# cyt4dn register map
Vendor: Cypress Semiconductor; Series: cyt4dn; File version: 1.0
CPU: CM7 r0p1, little endian, MPU, FPU, VTOR, 3 interrupt priority bits
Registers are 32-bit, read-write, reset 0x0 unless marked. A register's access mark holds for its fields unless they carry their own. Offsets are from the block's base; [hi:lo] are bit positions; lines under a group give offsets from that group; {n}, {i} and the like mark numbered series; 'fields as' and 'values as' point back to an identical list.

## VIDEOSS0 (part 7 of 18) — Video and Graphics Subsystem IP
Base 0x40A00000
0x80000 VIDEOIO group — Video I/O Core
  0x00 SUBIO group — Sub Interface
    0x10000 COMPENG group — Composition Engine
      0x4800 FETCHLAYER0 group — FetchLayer #0 (Display)
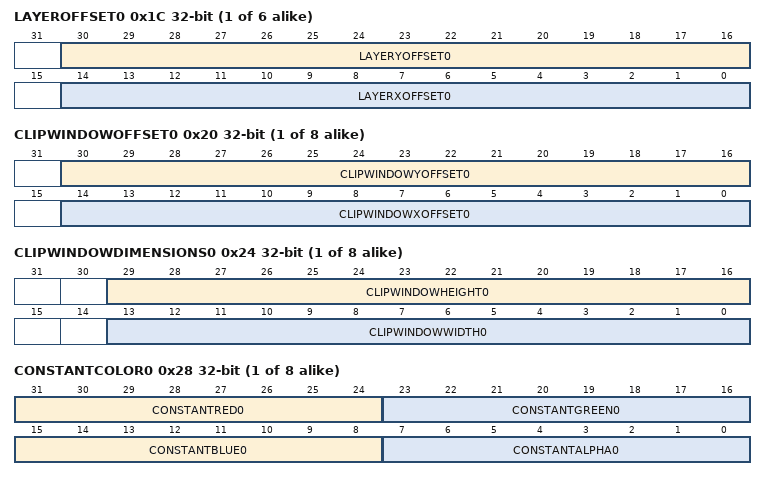
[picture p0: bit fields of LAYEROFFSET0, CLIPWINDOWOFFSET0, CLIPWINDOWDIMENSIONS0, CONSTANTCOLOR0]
        {0x1C+0x28*m} LAYEROFFSET{m} (m=0..5) — Position of layer {m} within the destination frame.
          [30:16] LAYERYOFFSET{m} — Vertical offset (Y). (format is signed integer)
          [14:0] LAYERXOFFSET{m} — Horizontal offset (X). (format is signed integer)
        {0x20+0x28*m} CLIPWINDOWOFFSET{m} (m=0..7) — Clip window position for layer {m}.
          [30:16] CLIPWINDOWYOFFSET{m} — Vertical position (Y). (format is signed integer)
          [14:0] CLIPWINDOWXOFFSET{m} — Horizontal position (X). (format is signed integer)
        {0x24+0x28*m} CLIPWINDOWDIMENSIONS{m} (m=0..7) — Clip window size for layer {m}.
          [29:16] CLIPWINDOWHEIGHT{m} — Height.
          [13:0] CLIPWINDOWWIDTH{m} — Width.
        {0x28+0x28*m} CONSTANTCOLOR{m} (m=0..7) — Constant color for layer {m}.
          [31:24] CONSTANTRED{m} — Red and Y (luma).
          [23:16] CONSTANTGREEN{m} — Green and U (chroma).
          [15:8] CONSTANTBLUE{m} — Blue and V (chroma).
          [7:0] CONSTANTALPHA{m} — Alpha.
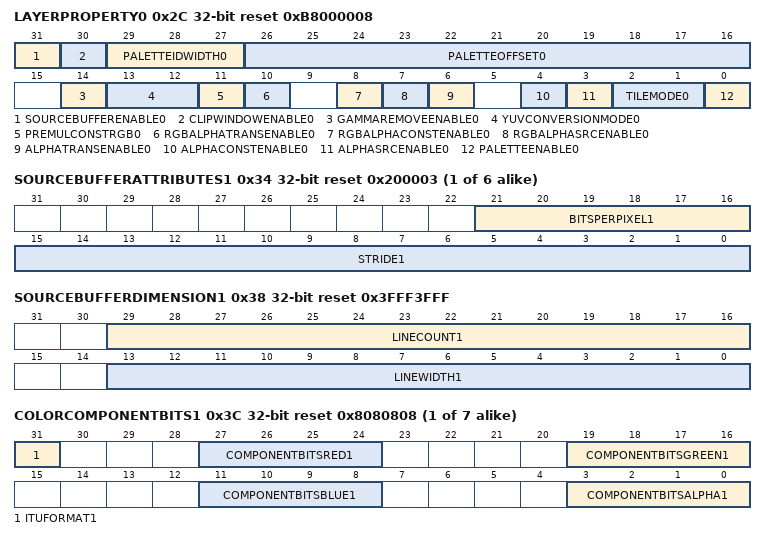
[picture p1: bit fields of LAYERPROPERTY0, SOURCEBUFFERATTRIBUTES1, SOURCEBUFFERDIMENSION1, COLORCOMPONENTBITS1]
        0x2C LAYERPROPERTY0 reset 0xB8000008 — Common properties of layer 0.
          [31] SOURCEBUFFERENABLE0 — Value 1 enables the source buffer for this layer. When disabled the tiling color is used only (TileMode TILE_PAD not allowed).
          [30] CLIPWINDOWENABLE0 — Value 1 enables the clip window for this layer. Pixels outside the clip window get the clip color, pixels inside the source or tiling color.
          [29:27] PALETTEIDWIDTH0 — Number minus one of least significant bits of pixel data read from the source buffer that are used as index value for color palette look-up.
          [26:16] PALETTEOFFSET0 — Palette may contain multiple areas. This offset shows to the starting position of the currently used area.
          [14] GAMMAREMOVEENABLE0 — Value 1 enables the stage to remove a gamma from RGB components.
          [13:12] YUVCONVERSIONMODE0 — Enables different kind of YUV to RGB conversions.
            0=OFF (No conversion.); 1=ITU601 (Conversion from YCbCr (YUV) to RGB according to ITU recommendation BT.601-6 (standard definition TV). Input range is 16..235 for Y and 16..240 for U/V.); 2=ITU601_FR (Conversion from YCbCr (YUV) to RGB according to ITU recommendation BT.601-6, but assuming full range YUV inputs (0..255). Most typically used for computer graphics (e.g. for JPEG encoding).); 3=ITU709 (Conversion from YCbCr (YUV) to RGB according to ITU recommendation BT.709-5 part 2 (high definition TV). Input range is 16..235 for Y and 16..240 for U/V.)
          [11] PREMULCONSTRGB0 — When enabled (value 1) the values given by ConstantRed/Green/Blue are used instead of alpha for source RGB pre-multiply. Settings RGBAlphaSrc/Const/Mask/TransEnable have no effect then.
          [10] RGBALPHATRANSENABLE0 — Value 1 enables transparent alpha (0 or 1 depending on RGB matching ConstantColor setting) for RGB pre-multiply. When disabled transparent alpha is set to 1.
          [8] RGBALPHACONSTENABLE0 — Value 1 enables constant alpha (ConstAlpha fields) for RGB pre-multiply. When disabled constant alpha is set to 1.
          [7] RGBALPHASRCENABLE0 — Value 1 enables source alpha (stored together with color component in the source buffer) for RGB pre-multiply. When disabled source alpha is set to 1.
          [6] ALPHATRANSENABLE0 — Value 1 enables transparent alpha for computing the output alpha. When disabled transparent alpha is set to 1.
          [4] ALPHACONSTENABLE0 — Value 1 enables constant alpha for computing the output alpha. When disabled constant alpha is set to 1.
          [3] ALPHASRCENABLE0 — Value 1 enables source alpha for computing the output alpha. When disabled source alpha is set to 1.
          [2:1] TILEMODE0 — Select the tile mode for pixels outside the source buffer. Clip color (0,0,0,0) takes precedence if a pixel becomes subject to both tiling and clipping.
            0=TILE_FILL_ZERO (Use zero value); 1=TILE_FILL_CONSTANT (Use constant color register value); 2=TILE_PAD (Use closest pixel from source buffer. Must not be used for DECODE or YUV422 operations or when SourceBufferEnable is 0.); 3=TILE_PAD_ZERO (Use closest pixel from source buffer but zero for alpha component. Must not be used for DECODE or YUV422 operations or when SourceBufferEnable is 0.)
          [0] PALETTEENABLE0 — Enables (value = 1) a color palette with 8 bits input and 24 bits output. Lower bits of the lookup index are read from memory (PaletteIdWidth0), upper bits are set to index of this layer. Palette output is extended by upper bits of index word read from memory (e.g. to store alpha together with index). Result is mapped to color channels according to ColorComponentBits/Shift settings.
        {0x8+0x28*m} BASEADDRESS{m} (m=1..7) — Source buffer base address of layer {m}.
          [31:0] BASEADDRESS{m} — See BaseAddress0.
        {0xC+0x28*m} SOURCEBUFFERATTRIBUTES{m} reset 0x200003 (m=1..6) — Source buffer attributes for layer {m}.
          [21:16] BITSPERPIXEL{m} — See BitsPerPixel0.
          [15:0] STRIDE{m} — See Stride0.
        0x38 SOURCEBUFFERDIMENSION1 reset 0x3FFF3FFF — Source buffer dimensions of layer 1,
          [29:16] LINECOUNT1 — See LineCount0.
          [13:0] LINEWIDTH1 — See LineWidth0.
        {0x14+0x28*m} COLORCOMPONENTBITS{m} reset 0x8080808 (m=1..7) — Size of color components for RGB, YUV and index formats (layer {m}).
          [31] ITUFORMAT{m} — See ITUFormat0.
          [27:24] COMPONENTBITSRED{m} — Red, Y (luma) and palette index.
          [19:16] COMPONENTBITSGREEN{m} — Green and U (chroma).
          [11:8] COMPONENTBITSBLUE{m} — Blue and V (chroma).
          [3:0] COMPONENTBITSALPHA{m} — Alpha.
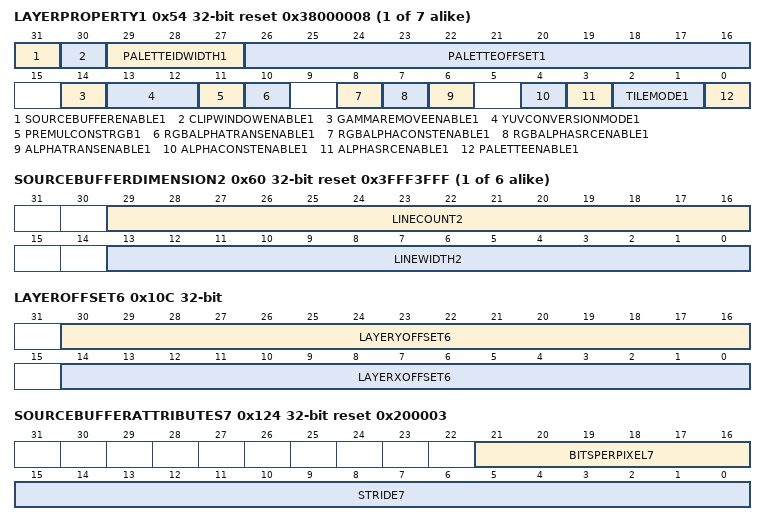
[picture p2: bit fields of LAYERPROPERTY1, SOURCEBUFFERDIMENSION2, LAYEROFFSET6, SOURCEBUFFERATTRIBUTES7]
        {0x2C+0x28*m} LAYERPROPERTY{m} reset 0x38000008 (m=1..7) — Common properties of layer {m}.
          [31] SOURCEBUFFERENABLE{m} — See SourceBufferEnable0.
          [30] CLIPWINDOWENABLE{m} — See ClipWindowEnable0.
          [29:27] PALETTEIDWIDTH{m} — see PaletteIdWidth0.
          [26:16] PALETTEOFFSET{m} — see PaletteOffset0.
          [14] GAMMAREMOVEENABLE{m} — See GammaRemoveEnable0.
          [13:12] YUVCONVERSIONMODE{m} — See YUVConversionMode0.
            values as VIDEOIO.SUBIO.COMPENG.FETCHLAYER0.LAYERPROPERTY0.YUVCONVERSIONMODE0
          [11] PREMULCONSTRGB{m} — See PremulConstRGB0.
          [10] RGBALPHATRANSENABLE{m} — See RGBAlphaTransSelect0.
          [8] RGBALPHACONSTENABLE{m} — See RGBAlphaConstSelect0.
          [7] RGBALPHASRCENABLE{m} — See RGBAlphaSrcSelect0.
          [6] ALPHATRANSENABLE{m} — See AlphaTransSelect0.
          [4] ALPHACONSTENABLE{m} — See AlphaConstSelect0.
          [3] ALPHASRCENABLE{m} — See AlphaSrcSelect0.
          [2:1] TILEMODE{m} — See TileMode0.
            values as VIDEOIO.SUBIO.COMPENG.FETCHLAYER0.LAYERPROPERTY0.TILEMODE0
          [0] PALETTEENABLE{m} — See PaletteEnable0.
        {0x10+0x28*m} SOURCEBUFFERDIMENSION{m} reset 0x3FFF3FFF (m=2..7) — Source buffer dimension of layer {m}.
          [29:16] LINECOUNT{m} — See LineCount0.
          [13:0] LINEWIDTH{m} — See LineWidth0.
        0x10C LAYEROFFSET6 — Position of layer 1 within the destination frame.
          [30:16] LAYERYOFFSET6 — Vertical offset (Y). (format is signed integer)
          [14:0] LAYERXOFFSET6 — Horizontal offset (X). (format is signed integer)
        0x124 SOURCEBUFFERATTRIBUTES7 reset 0x200003 — Source buffer stride for layer 7.
          [21:16] BITSPERPIXEL7 — See BitsPerPixel0.
          [15:0] STRIDE7 — See Stride0.
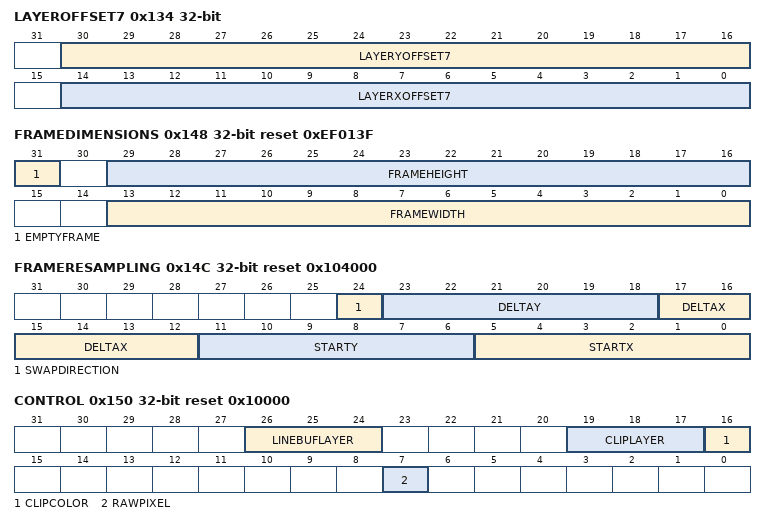
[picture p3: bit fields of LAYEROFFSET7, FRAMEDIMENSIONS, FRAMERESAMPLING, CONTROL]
        0x134 LAYEROFFSET7 — Position of layer 7 within the destination frame.
          [30:16] LAYERYOFFSET7 — Vertical offset (Y). (format is signed integer)
          [14:0] LAYERXOFFSET7 — Horizontal offset (X). (format is signed integer)
        0x148 FRAMEDIMENSIONS reset 0xEF013F — Output frame dimension.
          [31] EMPTYFRAME — When enabled output frame is empty. FrameWidth/Height settings have no effect then. Can be used to load shadows or to generate synchronization signals only (frame/sequence complete). If enabled, InputSelect must be set to INACTIVE.
          [29:16] FRAMEHEIGHT — Frame height minus one.
          [13:0] FRAMEWIDTH — Frame width minus one.
        0x14C FRAMERESAMPLING reset 0x104000 — Resampling options for output frame.
          [24] SWAPDIRECTION — Swaps X and Y directions for re-sampling. When enabled (= 1) DeltaY is applied for horizontal and DeltaX for vertical step on destination frame.
          [23:18] DELTAY — Increment of Y coordinate for vertical step in destination frame. (format is signed fix-point 4.2)
          [17:12] DELTAX — Increment of X coordinate for horizontal step in destination frame. (format is signed fix-point 4.2)
          [11:6] STARTY — Y coordinate of first sample point relative to origin. (format is signed fix-point 4.2)
          [5:0] STARTX — X coordinate of first sample point relative to origin. (format is signed fix-point 4.2)
        0x150 CONTROL reset 0x10000 — Shared common control settings for all layers.
          [26:24] LINEBUFLAYER — Index of the layer which used as a memory based linebuffer. Only has an effect if this fetch unit is connected to a store unit for linebuffer handshake and linebuffer handshake is enabled.
          [19:17] CLIPLAYER — Index of the layer which is used to fill the clipping area of the frame layout when ClipColor is set to LAYER. The selected layer must be enabled (LayerEnable).
          [16] CLIPCOLOR — Selects which color to take for pixels that do not lie inside the clip window of any layer.
            0=NULL (Null color.); 1=LAYER (Color of layer number given by ClipLayer (or layer 0 when Fetch unit has one layer only). The color is then the layer's source or tiling color.)
          [7] RAWPIXEL — Raw pixel mode. If enabled (value = 1), the ComponentBits/Shift settings are replaced for all layers by fixed values that allow passing the pixel data read from memory unchanged to subsequent units (e.g. for reading coordinate layers). Multiply stages and transparent color are deactivated. Skip and Tile pixels are not affected by this setting.
        0x154 TRIGGERENABLE — Shadow load enable flags for all layers.
          [7:0] SHDLDREQ — Shadow load request flags for each layer (one time load).
        0x158 CONTROLTRIGGER wo reset not defined — Shadow load trigger.
          [0] SHDTOKGEN — Writing a 1 to this will load shadow registers into the active configuration with the next start of frame and send a shadow load token to subsequent units.
        0x15C START wo reset not defined — Frame start trigger.
          [0] START — Writing a 1 to this field will start generating one frame (for debugging purposes only).
        0x160 FETCHTYPE ro reset not defined — Fetch unit type.
          [3:0] FETCHTYPE — This field can be used to determine what kind of fetch unit this is.
            0=DECODE (Fetch unit with RL and RLAD decoder.); 1=LAYER (Fetch unit with fractional plane (8 layers).); 2=WARP (Fetch unit with arbitrary warping and fractional plane (8 layers).); 3=ECO (Fetch unit with minimum feature set for alpha, chroma and coordinate planes.); 4=PERSP (Fetch unit with affine, perspective and arbitrary warping.); 5=ROT (Fetch unit with affine and arbitrary warping.); 6=DECODEL (Fetch unit with RL and RLAD decoder, reduced feature set.); 7=LAYERL (Fetch unit with fractional plane (8 layers), reduced feature set.); 8=ROTL (Fetch unit with affine and arbitrary warping, reduced feature set.); 9=ECOL (Fetch unit with reduced minimum feature set for alpha, chroma and coordinate planes.); 10=BLIT (Fetch unit with DECODE and PERSP capabilities.)
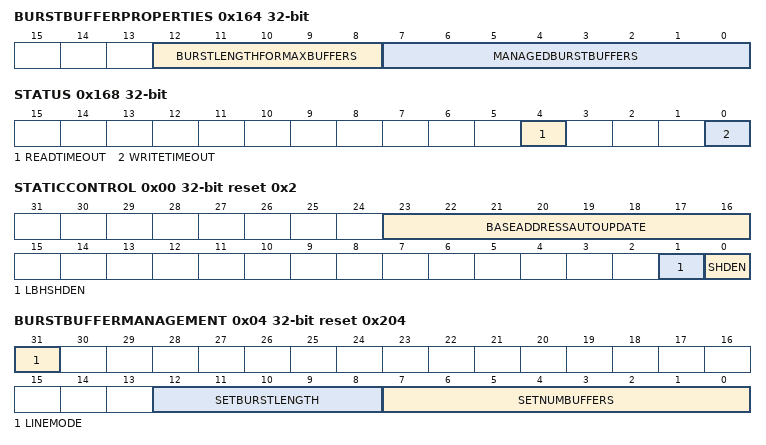
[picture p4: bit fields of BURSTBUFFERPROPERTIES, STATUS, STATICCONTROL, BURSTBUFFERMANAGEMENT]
        0x164 BURSTBUFFERPROPERTIES ro reset not defined
          [12:8] BURSTLENGTHFORMAXBUFFERS — Maximum Burst Length that can be used when ManagedBurstBuffers burst buffers are used.
          [7:0] MANAGEDBURSTBUFFERS — Maximum number of burst buffers that can be administrated in the AXI interface.
        0x168 STATUS — Status information.
          [4] READTIMEOUT — Timeout detected when reading from the palette entries or shadow token trigger enables in FetchLayer derivate. Write 1 to clear.
          [0] WRITETIMEOUT — Timeout detected when writing to the palette entries or shadow token trigger enables in FetchLayer derivate. Write 1 to clear.
      0x4C00 FETCHDECODE4 group — FetchDecode #4 (Capture)
        0x00 STATICCONTROL reset 0x2 — Common static control options.
          [23:16] BASEADDRESSAUTOUPDATE — Enable flag for continuous shadow load of BaseAddress field for each layer (layer index = bit index). When set to 1 the active BaseAddress configuration is loaded from shadow at start of each frame. This update is then executed independently from other RWS type fields. ShdEn must be enabled for this mode. When the flag is enabled for layer 0, also the FieldId0 shadow is automatically loaded.
          [1] LBHSHDEN — Enables shadowing of LBH configuration signals.
          [0] SHDEN — Enables shadowing of all RWS type registers (0=write_through, 1=shadowed).
        0x04 BURSTBUFFERMANAGEMENT reset 0x204 — AXI interface buffer management register
          [31] LINEMODE — Fetch buffer cache control.
            0=DISPLAY (Mandatory setting for operation in the Display Controller. Works also for Blit Engine with marginal performance impact.); 1=BLIT (Recommended setting for operation in the Blit Engine.)
          [12:8] SETBURSTLENGTH — Set this to the burst length that should be used on the AXI interface. SetNumBuffers * SetBurstLength has to be smaller or equal to ManagedBurstBuffers * BurstLengthForMaxBuffers and that bursts larger than 16 are not possible on the axi interface. Only a power of two may be specified as burst length.
          [7:0] SETNUMBUFFERS — Set this to the number of bursts that should be buffered. SetNumBuffers has to be smaller or equal to ManagedBurstBuffers and SetNumBuffers * SetBurstLength has to be smaller or equal to ManagedBurstBuffers * BurstLengthForMaxBuffers. Must be a power of 2. The minimum allowed settings is 4 except for the FetchEco derivate which has a minimum allowed setting of 2.
        0x08 RINGBUFSTARTADDR0 — Ring buffer setup for layer 0.
          [31:0] RINGBUFSTARTADDR0 — Start address of the ring buffer. Must be aligned to SetBurstLength x 8 bytes.
        0x0C RINGBUFWRAPADDR0 — Ring buffer setup for layer 0.
          [31:0] RINGBUFWRAPADDR0 — End address of the ring buffer (last byte of the buffer plus one).
        0x10 FRAMEPROPERTIES0 — Frame property setup for layer 0.
          [0] FIELDID0 — Field identifier that is generated for subsequent units (0 = progressive frame or interlaced field with even line indices, 1 = odd field).
        0x14 BASEADDRESS0 — Source buffer base address of layer 0.
          [31:0] BASEADDRESS0 — Byte aligned start address of the layer source buffer. For a pixel width of 32 bits or DECODE operations BaseAddress bits 1 downto 0 have to be 0 and for a pixel width of 16 bit BaseAddress[0] has to be 0.
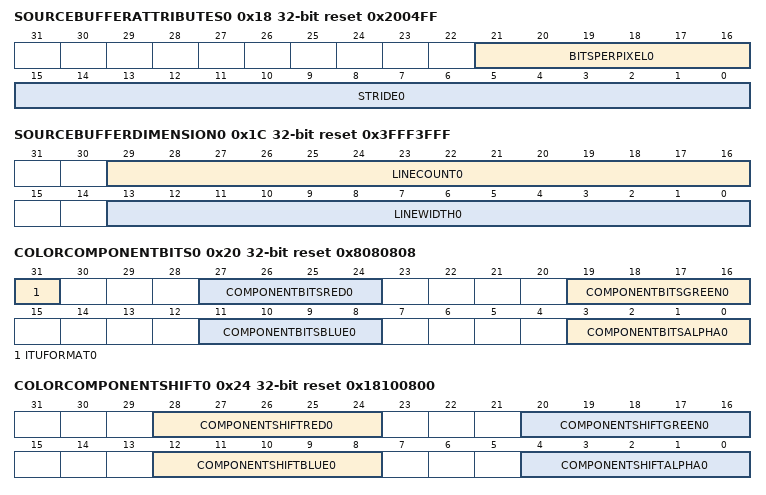
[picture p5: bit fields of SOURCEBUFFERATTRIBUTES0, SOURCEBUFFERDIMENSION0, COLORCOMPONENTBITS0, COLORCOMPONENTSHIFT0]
        0x18 SOURCEBUFFERATTRIBUTES0 reset 0x2004FF — Source buffer attributes for layer 0.
          [21:16] BITSPERPIXEL0 — Number of bits per pixel in the source buffer. Must be 1, 2, 4, 8, 16, 18, 24 or 32. [Exception] FetchEco does not support 18 and 24.
          [15:0] STRIDE0 — Source buffer stride of the layer in bytes minus one, used for address generation. For a pixel width of 32 bits Stride has to be dividable by 4 and given minus one and for a pixel width of 16 bit Stride has to be dividable by two and given minus one.
        0x1C SOURCEBUFFERDIMENSION0 reset 0x3FFF3FFF — Source buffer dimension of layer 0.
          [29:16] LINECOUNT0 — Number of lines of the source buffer of the layer minus one.
          [13:0] LINEWIDTH0 — Width of the source buffer of the layer in pixels minus one.
        0x20 COLORCOMPONENTBITS0 reset 0x8080808 — Size of color components for RGB, YUV and index formats (layer 0).
          [31] ITUFORMAT0 — When ComponentBitsRed/Green/Blue is set to 10 and this mode enabled (value 1), then input format is considered 8.2 instead of 10.0 bits (max color is 1020 instead of 1023). This is compliant to ITU 656 standard.
          [27:24] COMPONENTBITSRED0 — Red, Y (luma) and palette index.
          [19:16] COMPONENTBITSGREEN0 — Green and U (chroma).
          [11:8] COMPONENTBITSBLUE0 — Blue and V (chroma).
          [3:0] COMPONENTBITSALPHA0 — Alpha.
        0x24 COLORCOMPONENTSHIFT0 reset 0x18100800 — Bit position of color components for RGB, YUV and index formats (layer 0).
          [28:24] COMPONENTSHIFTRED0 — Red, Y (luma) and palette index.
          [20:16] COMPONENTSHIFTGREEN0 — Green and U (chroma).
          [12:8] COMPONENTSHIFTBLUE0 — Blue and V (chroma).
          [4:0] COMPONENTSHIFTALPHA0 — Alpha.
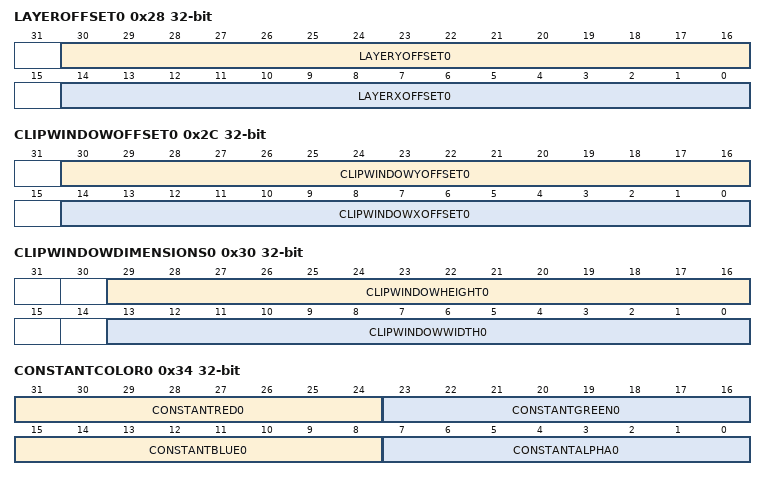
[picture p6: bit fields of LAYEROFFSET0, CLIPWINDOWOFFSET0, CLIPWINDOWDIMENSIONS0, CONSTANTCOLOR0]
        0x28 LAYEROFFSET0 — Position of layer 0 within the destination frame.
          [30:16] LAYERYOFFSET0 — Vertical offset (Y). (format is signed integer)
          [14:0] LAYERXOFFSET0 — Horizontal offset (X). (format is signed integer)
        0x2C CLIPWINDOWOFFSET0 — Clip window position for layer 0.
          [30:16] CLIPWINDOWYOFFSET0 — Vertical position (Y). (format is signed integer)
          [14:0] CLIPWINDOWXOFFSET0 — Horizontal position (X). (format is signed integer)
        0x30 CLIPWINDOWDIMENSIONS0 — Clip window size for layer 0.
          [29:16] CLIPWINDOWHEIGHT0 — Height.
          [13:0] CLIPWINDOWWIDTH0 — Width.
        0x34 CONSTANTCOLOR0 — Constant color for layer 0.
          [31:24] CONSTANTRED0 — Red and Y (luma).
          [23:16] CONSTANTGREEN0 — Green and U (chroma).
          [15:8] CONSTANTBLUE0 — Blue and V (chroma).
          [7:0] CONSTANTALPHA0 — Alpha.
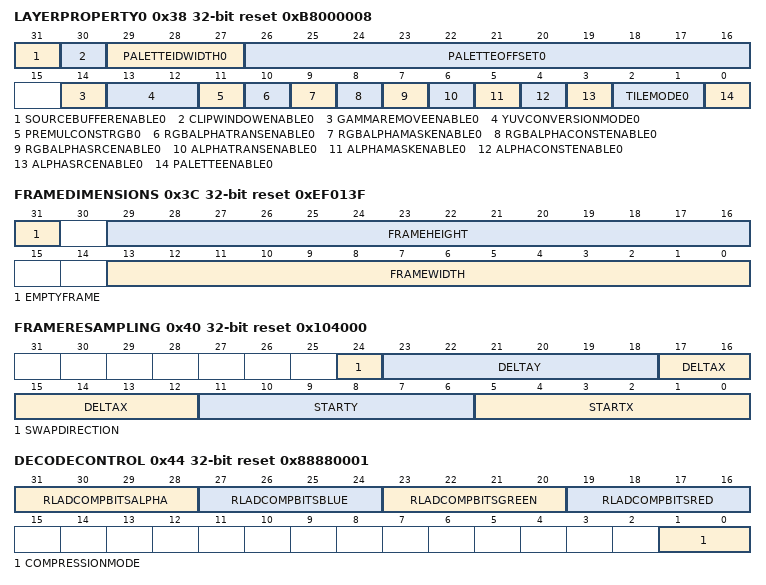
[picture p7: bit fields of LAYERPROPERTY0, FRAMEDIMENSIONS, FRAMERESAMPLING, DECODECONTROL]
        0x38 LAYERPROPERTY0 reset 0xB8000008 — Common properties of layer 0.
          [31] SOURCEBUFFERENABLE0 — Value 1 enables the source buffer for this layer. When disabled the tiling color is used only (TileMode TILE_PAD not allowed).
          [30] CLIPWINDOWENABLE0 — Value 1 enables the clip window for this layer. Pixels outside the clip window get the clip color, pixels inside the source or tiling color.
          [29:27] PALETTEIDWIDTH0 — Number minus one of least significant bits of pixel data read from the source buffer that are used as index value for color palette look-up.
          [26:16] PALETTEOFFSET0 — Palette may contain multiple areas. This offset shows to the starting position of the currently used area.
          [14] GAMMAREMOVEENABLE0 — Value 1 enables the stage to remove a gamma from RGB components.
          [13:12] YUVCONVERSIONMODE0 — Enables different kind of YUV to RGB conversions.
            values as VIDEOIO.SUBIO.COMPENG.FETCHLAYER0.LAYERPROPERTY0.YUVCONVERSIONMODE0
          [11] PREMULCONSTRGB0 — When enabled (value 1) the values given by ConstantRed/Green/Blue are used instead of alpha for source RGB pre-multiply. Settings RGBAlphaSrc/Const/Mask/TransEnable have no effect then.
          [10] RGBALPHATRANSENABLE0 — Value 1 enables transparent alpha (0 or 1 depending on RGB matching ConstantColor setting) for RGB pre-multiply. When disabled transparent alpha is set to 1.
          [9] RGBALPHAMASKENABLE0 — Value 1 enables mask alpha (read by another Fetch unit from a separate alpha layer) for RGB pre-multiply. When disabled mask alpha is set to 1. Alpha mask input must be enabled for this field to have effect.
          [8] RGBALPHACONSTENABLE0 — Value 1 enables constant alpha (ConstAlpha fields) for RGB pre-multiply. When disabled constant alpha is set to 1.
          [7] RGBALPHASRCENABLE0 — Value 1 enables source alpha (stored together with color component in the source buffer) for RGB pre-multiply. When disabled source alpha is set to 1.
          [6] ALPHATRANSENABLE0 — Value 1 enables transparent alpha for computing the output alpha. When disabled transparent alpha is set to 1.
          [5] ALPHAMASKENABLE0 — Value 1 enables mask alpha for computing the output alpha. When disabled mask alpha is set to 1.
          [4] ALPHACONSTENABLE0 — Value 1 enables constant alpha for computing the output alpha. When disabled constant alpha is set to 1.
          [3] ALPHASRCENABLE0 — Value 1 enables source alpha for computing the output alpha. When disabled source alpha is set to 1.
          [2:1] TILEMODE0 — Select the tile mode for pixels outside the source buffer. Clip color (0,0,0,0) takes precedence if a pixel becomes subject to both tiling and clipping.
            values as VIDEOIO.SUBIO.COMPENG.FETCHLAYER0.LAYERPROPERTY0.TILEMODE0
          [0] PALETTEENABLE0 — Enables (value = 1) a color palette with 8 bits input and 24 bits output. Lower bits of the lookup index are read from memory (PaletteIdWidth0), upper bits are set to index of this layer. Palette output is extended by upper bits of index word read from memory (e.g. to store alpha together with index). Result is mapped to color channels according to ColorComponentBits/Shift settings.
        0x3C FRAMEDIMENSIONS reset 0xEF013F — Output frame dimension.
          fields as VIDEOIO.SUBIO.COMPENG.FETCHLAYER0.FRAMEDIMENSIONS
        0x40 FRAMERESAMPLING reset 0x104000 — Resampling options for output frame.
          fields as VIDEOIO.SUBIO.COMPENG.FETCHLAYER0.FRAMERESAMPLING
        0x44 DECODECONTROL reset 0x88880001 — Control options for RLAD decompression.
          [31:28] RLADCOMPBITSALPHA — Maximum for average number of bits per compressed pixel for Alpha channel. This must match the corresponding encoder setting.
          [27:24] RLADCOMPBITSBLUE — Maximum for average number of bits per compressed pixel for Blue or V (chroma) channel. This must match the corresponding encoder setting.
          [23:20] RLADCOMPBITSGREEN — Maximum for average number of bits per compressed pixel for Green or U (chroma) channel. This must match the corresponding encoder setting.
          [19:16] RLADCOMPBITSRED — Maximum for average number of bits per compressed pixel for Red or Y (luma) channel. This must match the corresponding encoder setting.
          [1:0] COMPRESSIONMODE — Algorithm that the encoder used for compression.
            0=RLAD (Run-Length Adaptive Dithering (lossy compression).); 1=RLAD_UNIFORM (Run-Length Adaptive Dithering (lossy compression; uniform package size).); 2=RLA (Run-Length Adaptive (lossless compression).); 3=RL (Standard Run-Length. In contrary to other modes is in big endian format.)
        0x48 SOURCEBUFFERLENGTH — Source buffer length for compressed data.
          [28:0] RLEWORDS — Number of 32-bit words minus one that are required to decode the run length encoded source buffer.
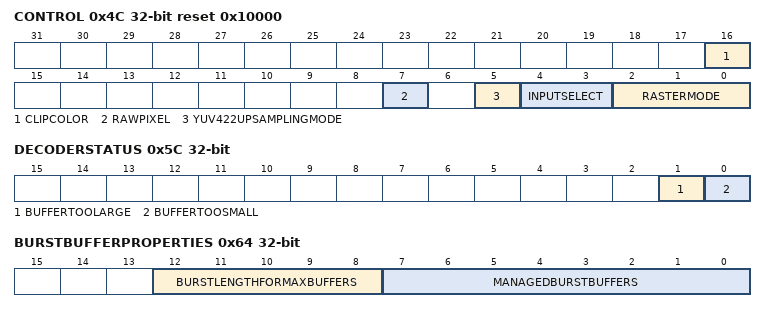
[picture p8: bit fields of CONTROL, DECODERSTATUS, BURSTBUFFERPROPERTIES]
        0x4C CONTROL reset 0x10000 — Shared common control settings for all layers.
          [16] CLIPCOLOR — Selects which color to take for pixels that do not lie inside the clip window of any layer.
            values as VIDEOIO.SUBIO.COMPENG.FETCHLAYER0.CONTROL.CLIPCOLOR
          [7] RAWPIXEL — Raw pixel mode. If enabled (value = 1), the ComponentBits/Shift settings are replaced for all layers by fixed values that allow passing the pixel data read from memory unchanged to subsequent units (e.g. for reading coordinate layers). Multiply stages and transparent color are deactivated. Skip and Tile pixels are not affected by this setting.
          [5] YUV422UPSAMPLINGMODE — Selects a method for horizontal up-sampling of YUV 422/420 input data.
            0=REPLICATE (Replicate mode for interspersed samples (UV samples between Y samples).); 1=INTERPOLATE (Interpolate mode for coaligned samples (UV samples at Y sample positions).)
          [4:3] INPUTSELECT — Selects function for the frame input port.
            0=INACTIVE (Not used.); 1=COMPPACK (Used for component packing (e.g. UV or source alpha buffer).); 2=ALPHAMASK (Used for RGB and alpha pre-multiply stage (mask alpha buffer).); 3=COORDINATE (Used for arbitrary warping (coordinate buffer).)
          [2:0] RASTERMODE — Selects a method how to generate source buffer sample points.
            0=NORMAL ([IBO only, for LBO use PERSPECTIVE with corresponding Geometry] First sample at StartX/Y relative to origin. Hor/ver increments using DeltaX/Y and DeltaSwap setup.); 1=DECODE ([FetchDecode/FetchBlit only] Source buffer is an encoded bit stream. First sample at origin (0,0). Hor/ver increments = (1,0)/(0,1).); 2=ARBITRARY ([FetchBlit/Warp only] Arbitrary warping (filter is active). Coordinates are read from frame input port. InputSelect must be set to COORDINATE. ArbStartX/Y and ArbDeltaXX/XY/YX/YY must be setup.); 3=PERSPECTIVE ([FetchBlit only] Affine/Perspective warping (filter is active). First sample at PerspStartX/Y/W. Hor/ver increments using PerspDeltaXX/XY/YX/YY/WX/WY. Homogeneous coordinates. See also field Geometry to reduce coordinate amount.); 4=YUV422 ([FetchBlit/Decode only] Source buffer is packed YUV 422. First sample at origin (0,0). Hor/ver increments = (1,0)/(0,1). All correllated window widths and horizontal offsets must be even.)
        0x50 CONTROLTRIGGER wo reset not defined — Shadow load trigger.
          fields as VIDEOIO.SUBIO.COMPENG.FETCHLAYER0.CONTROLTRIGGER
        0x54 START wo reset not defined — Frame start trigger.
          fields as VIDEOIO.SUBIO.COMPENG.FETCHLAYER0.START
        0x58 FETCHTYPE ro reset not defined — Fetch unit type.
          fields as VIDEOIO.SUBIO.COMPENG.FETCHLAYER0.FETCHTYPE
        0x5C DECODERSTATUS — Status information of the RLAD decoder.
          [1] BUFFERTOOLARGE — The buffer size given by RLEWords is too large. A complete output frame could be decoded, but more data was read than necessary.
          [0] BUFFERTOOSMALL — The buffer size given by RLEWords is too small. No complete output frame could be decoded.
        0x60 READADDRESS0 ro — Ring buffer synchronization for layer 0.
          [31:0] READADDRESS0 — Last burst address that was read from the layer's source buffer.
        0x64 BURSTBUFFERPROPERTIES ro reset not defined
          fields as VIDEOIO.SUBIO.COMPENG.FETCHLAYER0.BURSTBUFFERPROPERTIES
